# DEBUGSS_1.0 register map
Vendor: Texas Instruments
Peripheral module from a debugger description file (folder mspm33c321x).
Registers are 32-bit, read-write, no defined reset value unless marked. A register's access mark holds for its fields unless they carry their own. Offsets are as the file gives them; lines under a group give offsets from that group; [hi:lo] are bit positions; {n}, {i} and the like mark numbered series; 'fields as' and 'values as' point back to an identical list; <NAME> marks a mode.

## DEBUGSS
0x04 DEBUGSS_PINCM group
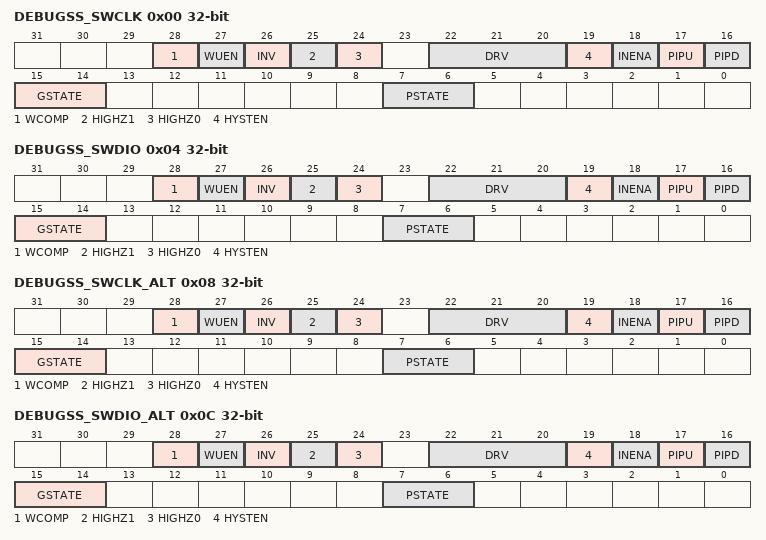
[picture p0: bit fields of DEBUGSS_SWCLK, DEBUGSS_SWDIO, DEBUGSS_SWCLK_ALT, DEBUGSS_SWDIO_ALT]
  0x00 DEBUGSS_SWCLK — SWCLK
    [28] WCOMP — Wake up compare value
      0=MATCH_ZERO (Match 0 will wake); 1=MATCH_ONE (Match 1 will wake)
    [27] WUEN — Wake up enable
      0=NO_WAKEUP (Wake up not enabled); 1=WAKEUP (Wake up enabled)
    [26] INV — Invert digital input/output relative to peripheral/GPIO
      0=NO_CHNG (Input and output are non-inverted); 1=CHNG (Input and output are inverted)
    [25] HIGHZ1 — High-Z instead of high output
      0=DRV_HIGH (Pin can be driven high); 1=DRV_HIZ (Pin is tri-stated instead of driven high)
    [24] HIGHZ0 — High-Z instead of low output
      0=DRV_LOW (Pin can be driven low); 1=DRV_HIZ (Pin is tri-stated instead of driven low)
    [22:20] DRV — Drive strength options
      0=STRENGTH_0 (Lowest drive strength); {v}=STRENGTH_{v} (Drive strength {v+1}/8) (v=1..6); 7=STRENGTH_7 (Highest drive strength)
    [19] HYSTEN — Hysteresis enable
      0=DIS_HYST (No hysteresis); 1=EN_HYST (Hysteresis on)
    [18] INENA — Input enable
      0=INP_DISABLE (Inputs 0 to connected core); 1=INP_ENABLE (Inputs IO pad value to connected core)
    [17] PIPU — Pull up enable
      0=NO_PULL_UP; 1=PULL_UP
    [16] PIPD — Pull down enable
      0=NO_PULL_DOWN; 1=PULL_DOWN
    [15:14] GSTATE — GPIO Channel State
      0=UNASSIGNED (G-Channel is in Unassigned State); 1=HANDOVER (G-Channel is in Handover State); 2=CONC_NOT_LOCKED (G-Channel is in Connected State and not Locked (That is F field is allowed to change without going back through Unassigned state)); 3=CONC_LOCKED (G-Channel is in Connected State and Locked (That is F field is not allowed to change to a different non-Zero value until both G and P channels go to Unassigned))
    [7:6] PSTATE — Peripheral-Analog Channel State
      0=UNASSIGNED (P-Channel is in Unassigned State); 1=HANDOVER (P-Channel is in Handover State); 2=CONC_NOT_LOCKED (P-Channel is in Connected State and not Locked (That is F field is allowed to change without going back through Unassigned state)); 3=CONC_LOCKED (P-Channel is in Connected State and Locked (That is F field is not allowed to change to a different non-Zero value until both G and P channels go to Unassigned))
  0x04 DEBUGSS_SWDIO — SWDIO
    fields as DEBUGSS_PINCM.DEBUGSS_SWCLK
  0x08 DEBUGSS_SWCLK_ALT — SWCLK_ALT
    fields as DEBUGSS_PINCM.DEBUGSS_SWCLK
  0x0C DEBUGSS_SWDIO_ALT — SWDIO_ALT
    fields as DEBUGSS_PINCM.DEBUGSS_SWCLK
0x480 DEBUGSS_CPU_CONNECT_0 — CPU Connect
  [1] CPUSS0_CONN — CPUSS0 connect bit.
    0=UNCONNECTED (The CPU is not connected.); 1=CONNECTED (The CPU is connected.)
0x1020 DEBUGSS_CPU_INT group
  0x00 DEBUGSS_IIDX — Interrupt index
    [7:0] STAT — Interrupt index status
      0=NO_INTR (No pending interrupt request); 1=TXIFG (TX interrupt); 2=RXIFG (RX interrupt); 3=PWRUP (Power-up interrupt. A debug session has started.); 4=PWRDWN (Power-up interrupt. A debug session has started.)
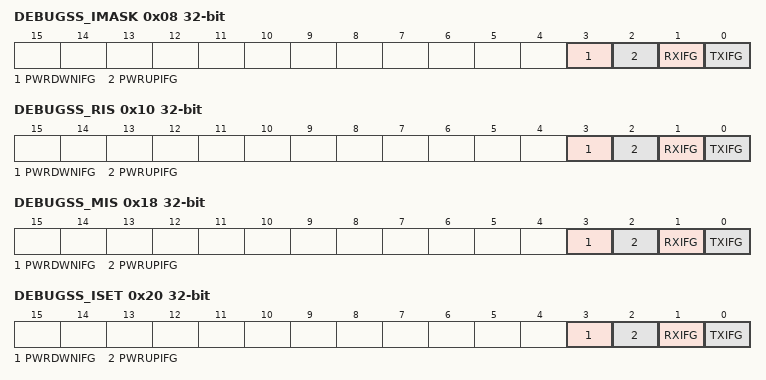
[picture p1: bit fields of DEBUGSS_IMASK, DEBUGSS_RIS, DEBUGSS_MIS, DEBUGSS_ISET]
  0x08 DEBUGSS_IMASK — Interrupt mask
    [all] fields
      0=CLR (Interrupt is masked out); 1=SET (Interrupt will request an interrupt service routine and corresponding bit in MIS will be set)
    [3] PWRDWNIFG — Masks PWRDWNIFG in MIS register
    [2] PWRUPIFG — Masks PWRUPIFG in MIS register
    [1] RXIFG — Masks RXIFG in MIS register
    [0] TXIFG — Masks TXIFG in MIS register
  0x10 DEBUGSS_RIS — Raw interrupt status
    [3] PWRDWNIFG — Raw interrupt status for PWRDWNIFG
      0=CLR (PWRUPIFG did not occur); 1=SET (PWRUPIFG occurred)
    [2] PWRUPIFG — Raw interrupt status for PWRUPIFG
      0=CLR (PWRUPIFG did not occur); 1=SET (PWRUPIFG occurred)
    [1] RXIFG — Raw interrupt status for RXIFG
      0=CLR (RXIFG did not occur); 1=SET (RXIFG occurred)
    [0] TXIFG — Raw interrupt status for TXIFG
      0=CLR (TXIFG did not occur); 1=SET (TXIFG occurred)
  0x18 DEBUGSS_MIS — Masked interrupt status
    [3] PWRDWNIFG — Masked interrupt status for PWRDWNIFG
      0=CLR (PWRUPIFG did not request an interrupt service routine); 1=SET (PWRUPIFG requests an interrupt service routine)
    [2] PWRUPIFG — Masked interrupt status for PWRUPIFG
      values as PWRDWNIFG
    [1] RXIFG — Masked interrupt status for RXIFG
      0=CLR (RXIFG did not request an interrupt service routine); 1=SET (RXIFG requests an interrupt service routine)
    [0] TXIFG — Masked interrupt status for TXIFG
      0=CLR (TXIFG did not request an interrupt service routine); 1=SET (TXIFG requests an interrupt service routine)
  0x20 DEBUGSS_ISET — Interrupt set
    [3] PWRDWNIFG — Sets PWRDWNIFG in RIS register
      0=NO_EFFECT (Writing a 0 has no effect); 1=SET (RIS bit corresponding to PWRUPIFG is set)
    [2] PWRUPIFG — Sets PWRUPIFG in RIS register
      values as PWRDWNIFG
    [1] RXIFG — Sets RXIFG in RIS register
      0=NO_EFFECT (Writing a 0 has no effect); 1=SET (RIS bit corresponding to RXIFG is set)
    [0] TXIFG — Sets TXIFG in RIS register
      0=NO_EFFECT (Writing a 0 has no effect); 1=SET (RIS bit corresponding to TXIFG is set)
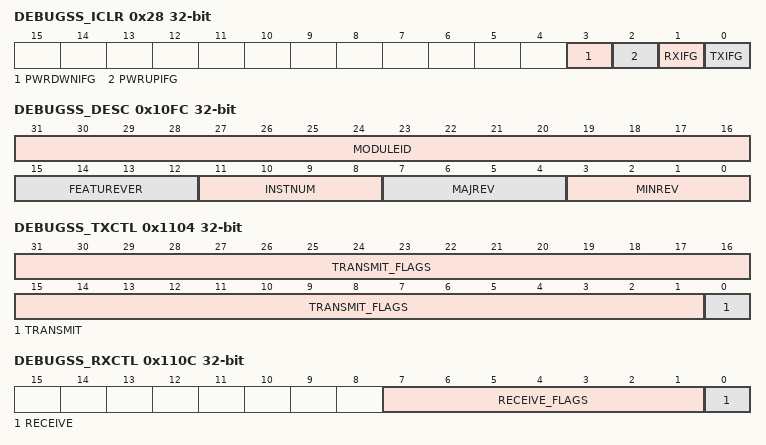
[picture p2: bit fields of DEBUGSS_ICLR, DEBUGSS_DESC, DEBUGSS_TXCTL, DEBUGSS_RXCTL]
  0x28 DEBUGSS_ICLR — Interrupt clear
    [3] PWRDWNIFG — Clears PWRDWNIFG in RIS register
      0=NO_EFFECT (Writing a 0 has no effect); 1=CLR (RIS bit corresponding to PWRUPIFG is cleared)
    [2] PWRUPIFG — Clears PWRUPIFG in RIS register
      values as PWRDWNIFG
    [1] RXIFG — Clears RXIFG in RIS register
      0=NO_EFFECT (Writing a 0 has no effect); 1=CLR (RIS bit corresponding to RXIFG is cleared)
    [0] TXIFG — Clears TXIFG in RIS register
      0=NO_EFFECT (Writing a 0 has no effect); 1=CLR (RIS bit corresponding to TXIFG is cleared)
0x10E0 DEBUGSS_EVT_MODE ro — Event Mode
  [1:0] INT0_CFG — Event line mode select for peripheral events
    0=DISABLE (The interrupt or event line is disabled.); 1=SOFTWARE (The interrupt or event line is in software mode. Software must clear the RIS.); 2=HARDWARE (The interrupt or event line is in hardware mode. The hardware (another module) clears automatically the associated RIS flag.)
0x10FC DEBUGSS_DESC — Module Description
  [31:16] MODULEID — Module identification contains a unique peripheral identification number. The assignments are maintained in a central database for all of the platform modules to ensure uniqueness.
  [15:12] FEATUREVER — Feature Set for the module *instance*
  [11:8] INSTNUM — Instance Number within the device. This will be a parameter to the RTL for modules that can have multiple instances
  [7:4] MAJREV — Major rev of the IP
  [3:0] MINREV — Minor rev of the IP
0x1100 DEBUGSS_TXD access not given — Transmit data register
0x1104 DEBUGSS_TXCTL ro — Transmit control register
  [31:1] TRANSMIT_FLAGS — Generic TX flags that can be set by external debug tool. Functionality is defined by SW.
  [0] TRANSMIT — Indicates data request in DSSM.TXD, set on write via Debug AP to DSSM.TXD. A read of the DSSM.TXD register by SW will clear the TX field. The tool can check that TXD is empty by reading this field.
    0=EMPTY (TXD is empty); 1=FULL (TXD is full)
0x1108 DEBUGSS_RXD access not given — Receive data register
0x110C DEBUGSS_RXCTL access per field — Receive control register
  [7:1] RECEIVE_FLAGS rw — Generic RX flags that can be set by SW and read by external debug tool. Functionality is defined by SW.
  [0] RECEIVE ro — Indicates SW write to the DSSM.RXD register. A read of the DSSM.RXD register by SWD Access Port will clear the RX field.
    0=EMPTY (RXD empty); 1=FULL (RXD full)
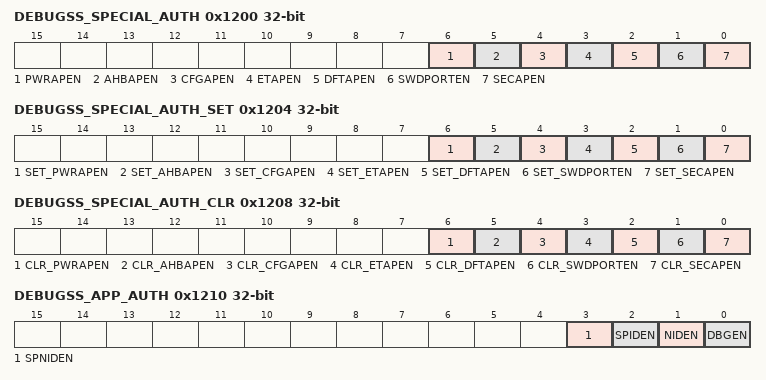
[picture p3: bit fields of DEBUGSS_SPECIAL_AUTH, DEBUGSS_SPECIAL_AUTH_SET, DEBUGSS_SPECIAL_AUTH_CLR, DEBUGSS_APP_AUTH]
0x1200 DEBUGSS_SPECIAL_AUTH ro — Special enable authorization register
  [6] PWRAPEN — An active high input. When asserted (and SWD access is also permitted), the debug tools can then access the PWR-AP to power and reset state of the CPU. When deasserted, a DAPBUS firewall will isolate the AP and prevent access.
    0=DISABLE (Disable PWR-AP); 1=ENABLE (Enable PWR-AP)
  [5] AHBAPEN — Disabling / enabling debug access to the M0+ Core via the AHB-AP DAP bus isolation.
    0=DISABLE (Disable AHB-AP); 1=ENABLE (Enable AHB-AP)
  [4] CFGAPEN — An active high input. When asserted (and SWD access is also permitted), the debug tools can use the Config-AP to read device configuration information. When deasserted, a DAPBUS firewall will isolate the AP and prevent access to the Config-AP.
    0=DISABLE (Disable CFG-AP); 1=ENABLE (Enable CFG-AP)
  [3] ETAPEN — An active high input. When asserted (and SWD access is also permitted), the debug tools can then access an ET-AP external to the DebugSS lite. When deasserted, a DAPBUS firewall will isolate the AP and prevent access.
    0=DISABLE (Disable ET+ -AP); 1=ENABLE (Enable ET+ -AP)
  [2] DFTAPEN — An active high input. When asserted (and SWD access is also permitted), the debug tools can then access the DFT-AP external to the DebugSS lite. When deasserted, a DAPBUS firewall will isolate the AP and prevent access.
    0=DISABLE (Disable DFT-TAP); 1=ENABLE (Enable DFT-TAP)
  [1] SWDPORTEN — When asserted, the SW-DP functions normally. When deasserted, the SW-DP effectively disables all external debug access.
    0=DISABLE (Disable SWD port); 1=ENABLE (Enable SWD port)
  [0] SECAPEN — An active high input. When asserted (and SWD access is also permitted), the debug tools can use the Security-AP to communicate with security control logic. When deasserted, a DAPBUS firewall will isolate the AP and prevent access to the Security-AP.
    0=DISABLE (Disable SEC-AP); 1=ENABLE (Enable SEC-AP)
0x1204 DEBUGSS_SPECIAL_AUTH_SET — Special enable authorization set register
  [6] SET_PWRAPEN — This bit sets PWRAPEN in SPECIAL_AUTH register.
    0=NO_EFFECT (Writing 0 has no effect); 1=SET (Set PWRAPEN)
  [5] SET_AHBAPEN — This bit sets AHBAPEN in SPECIAL_AUTH register.
    0=NO_EFFECT (Writing 0 has no effect); 1=SET (Set AHBAPEN)
  [4] SET_CFGAPEN — This bit sets CFGAPEN in SPECIAL_AUTH register.
    0=NO_EFFECT (Writing 0 has no effect); 1=SET (Set CFGAPEN)
  [3] SET_ETAPEN — This bit sets ETAPEN in SPECIAL_AUTH register.
    0=NO_EFFECT (Writing 0 has no effect); 1=SET (Set ETAPEN)
  [2] SET_DFTAPEN — This bit sets DFTAPEN in SPECIAL_AUTH register.
    0=NO_EFFECT (Writing 0 has no effect); 1=SET (Set DFTTAPEN)
  [1] SET_SWDPORTEN — This bit sets SWDPORTEN in SPECIAL_AUTH register.
    0=NO_EFFECT (Writing 0 has no effect); 1=SET (Set SWDPORTEN)
  [0] SET_SECAPEN — This bit sets SECAPEN bit in SPECIAL_AUTH register.
    0=NO_EFFECT (Writing 0 has no effect); 1=SET (Set SECAPEN)
0x1208 DEBUGSS_SPECIAL_AUTH_CLR — Special enable authorization clear register
  [6] CLR_PWRAPEN — This bit clears PWRAPEN in SPECIAL_AUTH register.
    0=NO_EFFECT (Writing 0 has no effect); 1=CLR (Clear PWRAPEN)
  [5] CLR_AHBAPEN — This bit clears AHBAPEN in SPECIAL_AUTH register.
    0=NO_EFFECT (Writing 0 has no effect); 1=CLR (Clear AHBAPEN)
  [4] CLR_CFGAPEN — This bit clears CFGAPEN in SPECIAL_AUTH register.
    0=NO_EFFECT (Writing 0 has no effect); 1=CLR (Clear CFGAPEN)
  [3] CLR_ETAPEN — This bit clears ETAPEN in SPECIAL_AUTH register.
    0=NO_EFFECT (Writing 0 has no effect); 1=CLR (Clear ETAPEN)
  [2] CLR_DFTAPEN — This bit clears DFTTAPEN in SPECIAL_AUTH register.
    0=NO_EFFECT (Writing 0 has no effect); 1=CLR (Clear DFTTAPEN)
  [1] CLR_SWDPORTEN — This bit clears SWDPORTEN in SPECIAL_AUTH register.
    0=NO_EFFECT (Writing 0 has no effect); 1=CLR (Clears SWDPORTEN)
  [0] CLR_SECAPEN — This bit clears SECAPEN bit in SPECIAL_AUTH register.
    0=NO_EFFECT (Writing 0 has no effect); 1=CLR (Clear SECAPEN)
0x1210 DEBUGSS_APP_AUTH ro — Application CPU0 authorization register
  [3] SPNIDEN — Secure non-invasive debug enable.
    0=DISABLE (Invasive debug disabled); 1=ENABLE (Invasive debug enabled)
  [2] SPIDEN — Secure invasive debug enable.
    values as SPNIDEN
  [1] NIDEN — Controls non-invasive debug enable.
    0=DISABLE (Non-invasive debug disabled); 1=ENABLE (Non-invasive debug enabled)
  [0] DBGEN — Controls invasive debug enable.
    values as SPNIDEN
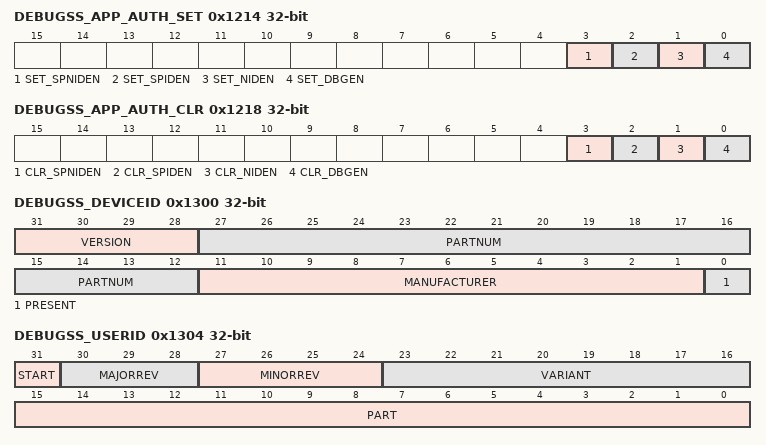
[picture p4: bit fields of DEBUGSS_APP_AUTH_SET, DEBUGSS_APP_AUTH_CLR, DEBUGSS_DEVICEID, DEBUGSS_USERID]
0x1214 DEBUGSS_APP_AUTH_SET — Application CPU0 authorization set register
  [3] SET_SPNIDEN — Sets SPNIDEN bit in APPCPU0_AUTH register.
    0=NO_EFFECT (Writing 0 has no effect); 1=SET (Sets NIDEN)
  [2] SET_SPIDEN — Sets SPIDEN bit in APPCPU0_AUTH register.
    0=NO_EFFECT (Writing 0 has no effect); 1=SET (Sets NIDEN)
  [1] SET_NIDEN — Sets NIDEN bit in APPCPU0_AUTH register.
    0=NO_EFFECT (Writing 0 has no effect); 1=SET (Sets NIDEN)
  [0] SET_DBGEN — Sets DBGEN bit in APPCPU0_AUTH register.
    0=NO_EFFECT (Writing 0 has no effect); 1=SET (Sets DBGEN)
0x1218 DEBUGSS_APP_AUTH_CLR — Application CPU0 authorization clear register
  [3] CLR_SPNIDEN — Clears SPNIDEN bit in APPCPU0_AUTH register.
    0=NO_EFFECT (Writing 0 has no effect); 1=SET (Sets NIDEN)
  [2] CLR_SPIDEN — Clears SPIDEN bit in APPCPU0_AUTH register.
    0=NO_EFFECT (Writing 0 has no effect); 1=SET (Sets NIDEN)
  [1] CLR_NIDEN — Clears NIDEN bit in APPCPU0_AUTH register.
    0=NO_EFFECT (Writing 0 has no effect); 1=CLR (Clears NIDEN)
  [0] CLR_DBGEN — Clears DBGEN bit in APPCPU0_AUTH register.
    0=NO_EFFECT (Writing 0 has no effect); 1=CLR (Clears DBGEN)
0x1300 DEBUGSS_DEVICEID ro — Device identification register
  [31:28] VERSION — Revision of the device.
    0=MIN (Minimum revision); 15=MAX (Maximium revision)
  [27:12] PARTNUM — Part number of the device.
    0=MIN (Minimum part number); 0xFFFF=MAX (Maximum part number)
  [11:1] MANUFACTURER — TI's JEDEC bank and company code, which is 00000010111b.
    23=TIJEDEC (TI's JDEC ID)
  [0] PRESENT — The value of 1 in bit 0 of the device identification register means the device idetifiaction is present.
    0=NOK (Not-Okay. The Device-ID is not present.); 1=OK (Okay. The Device-ID is present.)
0x1304 DEBUGSS_USERID ro — User code identification regsiter
  [31] START — Start bit. A value of 1 indicates the USERID is present.
    0=NOK (Not-Okay. The User-ID is not defined.); 1=OK (Okay. Start of the User-ID)
  [30:28] MAJORREV — Monotonic increasing value indicating a new revision of the device significant enough that users of the device may have to revise PCB or software design.
    0=MIN (Minimum major revision); 7=MAX (Maximum major revision)
  [27:24] MINORREV — Monotonic increasing value indicating a new revision of the device that preservs compatibility with lesser minorrev values.
    0=MIN (Minimum minor revision); 15=MAX (Maximum minor revision)
  [23:16] VARIANT — Bit pattern uniqueley identifies the variant of the part.
    0=MIN (Minimum variant); 255=MAX (Maximum variant)
  [15:0] PART — Bit pattern that uniquely identifies the part.
    values as DEBUGSS_DEVICEID.PARTNUM
